# AT32F457xx_v2 register map
Vendor: Keil; Series: AT32F457; File version: 1.0
CPU: CM4 r0p1, little endian, no MPU, FPU, 4 interrupt priority bits
Registers are 32-bit, read-write, reset 0x0 unless marked. A register's access mark holds for its fields unless they carry their own. Offsets are from the block's base; [hi:lo] are bit positions; {n}, {i} and the like mark numbered series; 'fields as' and 'values as' point back to an identical list.

## ERTC — Real-time clock
Base 0x40002800
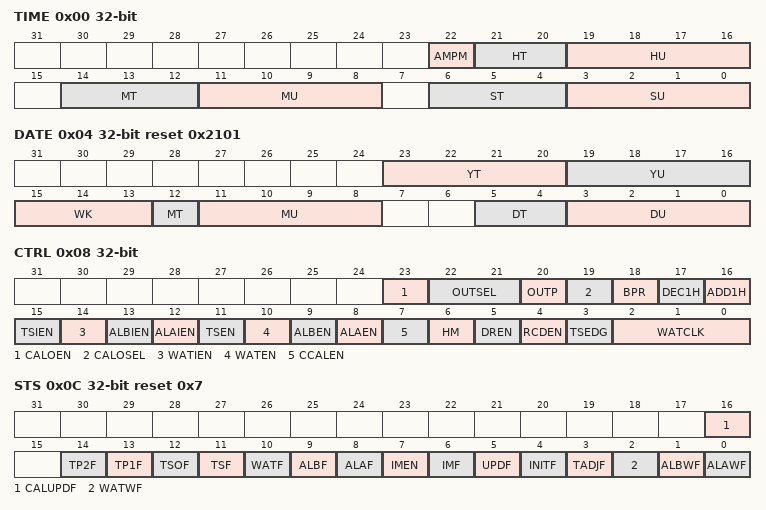
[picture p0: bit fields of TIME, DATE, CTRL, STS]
0x00 TIME
  [22] AMPM — AM/PM notation
  [21:20] HT — Hour tens
  [19:16] HU — Hour units
  [14:12] MT — Minute tens
  [11:8] MU — Minute units
  [6:4] ST — Second tens
  [3:0] SU — Second units
0x04 DATE reset 0x2101
  [23:20] YT — Year tens
  [19:16] YU — Year units
  [15:13] WK — Week
  [12] MT — Month tens
  [11:8] MU — Month units
  [5:4] DT — Date tens
  [3:0] DU — Date units
0x08 CTRL — control register
  [23] CALOEN — Calibration output enable
  [22:21] OUTSEL — Output source selection
  [20] OUTP — Output polarity
  [19] CALOSEL — Calibration output selection
  [18] BPR — Battery power domain data register
  [17] DEC1H — Decrease 1 hour
  [16] ADD1H — Add 1 hour
  [15] TSIEN — Timestamp interrupt enable
  [14] WATIEN — Wakeup timer interrupt enable
  [13] ALBIEN — Alarm B interrupt enable
  [12] ALAIEN — Alarm A interrupt enable
  [11] TSEN — Timestamp enable
  [10] WATEN — Wakeup timer enable
  [9] ALBEN — Alarm B enable
  [8] ALAEN — Alarm A enable
  [7] CCALEN — Coarse calibration enable
  [6] HM — Hour mode
  [5] DREN — Date/time register direct read enable
  [4] RCDEN — Reference clock detection enable
  [3] TSEDG — Timestamp trigger edge
  [2:0] WATCLK — Wakeup timer clock selection
0x0C STS reset 0x7 — initialization and status register
  [16] CALUPDF ro — Calibration value update completed flag
  [14] TP2F — Tamper detection 2 flag
  [13] TP1F — Tamper detection 1 flag
  [12] TSOF — Timestamp overflow flag
  [11] TSF — Timestamp flag
  [10] WATF — Wakeup timer flag
  [9] ALBF — Alarm B flag
  [8] ALAF — Alarm A flag
  [7] IMEN — Initialization mode enable
  [6] IMF ro — Enter initialization mode flag
  [5] UPDF — Calendar update flag
  [4] INITF ro — Calendar initialization flag
  [3] TADJF — Time adjustment flag
  [2] WATWF ro — Wakeup timer register allows write flag
  [1] ALBWF ro — Alarm B register allows write flag
  [0] ALAWF ro — Alarm A register allows write flag
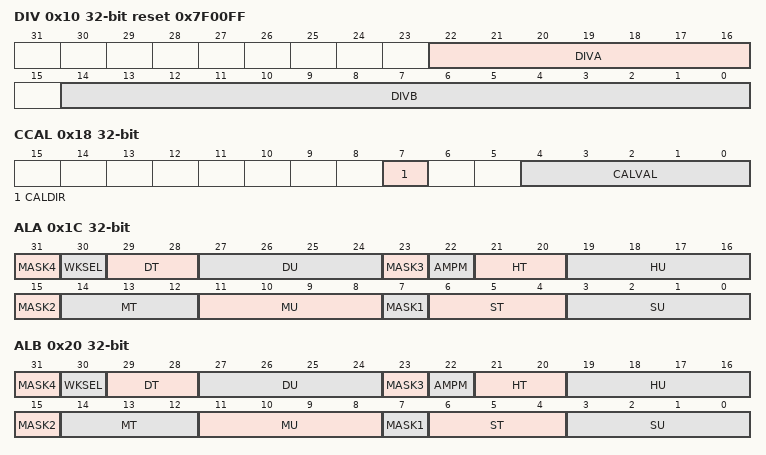
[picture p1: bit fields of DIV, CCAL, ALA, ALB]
0x10 DIV reset 0x7F00FF — Diveder register
  [22:16] DIVA — Diveder A
  [14:0] DIVB — Diveder B
0x14 WAT reset 0xFFFF — Wakeup timer register
  [15:0] VAL — Wakeup timer reload value
0x18 CCAL — Calibration register
  [7] CALDIR — Calibration direction
  [4:0] CALVAL — Calibration value
0x1C ALA — Alarm A register
  [31] MASK4 — Date/week mask
  [30] WKSEL — Date/week mode select
  [29:28] DT — Date tens
  [27:24] DU — Date units
  [23] MASK3 — Hours mask
  [22] AMPM
  [21:20] HT — Hour tens
  [19:16] HU — Hour units
  [15] MASK2 — Minutes mask
  [14:12] MT — Minute tens
  [11:8] MU — Minute units
  [7] MASK1 — Seconds mask
  [6:4] ST — Second tens
  [3:0] SU — Second units
0x20 ALB — Alarm B register
  fields as ALA
0x24 WP wo — write protection register
  [7:0] CMD — Command register
0x28 SBS ro — sub second register
  [15:0] SBS — Sub second value
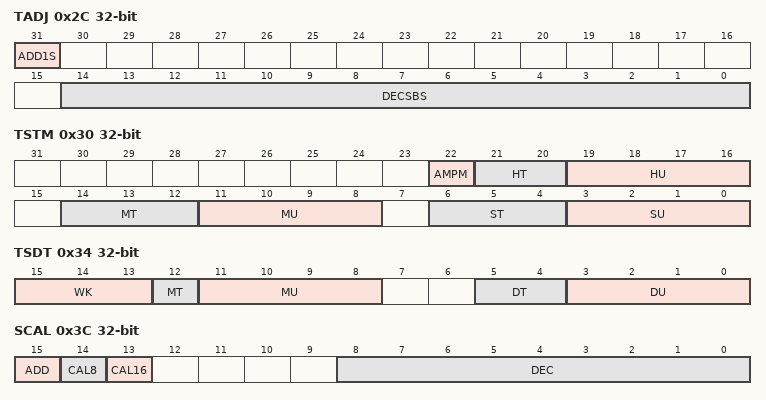
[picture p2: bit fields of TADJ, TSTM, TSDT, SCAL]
0x2C TADJ wo — time adjust register
  [31] ADD1S — Add 1 second
  [14:0] DECSBS — Decrease sub-second value
0x30 TSTM ro — time stamp time register
  [22] AMPM
  [21:20] HT — Hour tens
  [19:16] HU — Hour units
  [14:12] MT — Minute tens
  [11:8] MU — Minute units
  [6:4] ST — Second tens
  [3:0] SU — Second units
0x34 TSDT ro — timestamp date register
  [15:13] WK — Week
  [12] MT — Month tens
  [11:8] MU — Month units
  [5:4] DT — Date tens
  [3:0] DU — Date units
0x38 TSSBS ro — timestamp sub second register
  [15:0] SBS — Sub second value
0x3C SCAL — calibration register
  [15] ADD — Add ERTC clock
  [14] CAL8 — 8-second calibration period
  [13] CAL16 — 16 second calibration period
  [8:0] DEC — Decrease ERTC clock
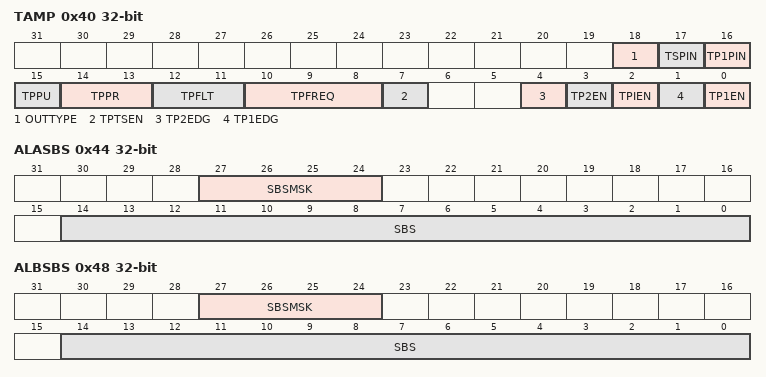
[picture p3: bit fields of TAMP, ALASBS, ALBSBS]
0x40 TAMP — tamper and alternate function configuration register
  [18] OUTTYPE — Output type
  [17] TSPIN — Time stamp detection pin selection
  [16] TP1PIN — Tamper detection pin selection
  [15] TPPU — Tamper detection pull-up
  [14:13] TPPR — Tamper detection pre-charge time
  [12:11] TPFLT — Tamper detection filter time
  [10:8] TPFREQ — Tamper detection frequency
  [7] TPTSEN — Tamper detection timestamp enable
  [4] TP2EDG — Tamper detection 2 valid edge
  [3] TP2EN — Tamper detection 2 enable
  [2] TPIEN — Tamper detection interrupt enable
  [1] TP1EDG — Tamper detection 1 valid edge
  [0] TP1EN — Tamper detection 1 enable
0x44 ALASBS — alarm A sub second register
  [27:24] SBSMSK — Sub-second mask
  [14:0] SBS — Sub-seconds value
0x48 ALBSBS — alarm B sub second register
  [27:24] SBSMSK — Sub-second mask
  [14:0] SBS — Sub-seconds value
{0x4C+4i} BPR{i}DT (i=1..20) — Battery powered domain register
  [31:0] DT — Battery powered domain data

## Notices in the file
Copyright (C) 2012-2014 ARM Limited. All rights reserved.
Purpose: System Viewer Description (SVD) Example (Schema Version 1.1)
This is a description of a none-existent and incomplete device
for demonstration purposes only.
Redistribution and use in source and binary forms, with or without
modification, are permitted provided that the following conditions are met:
- Redistributions of source code must retain the above copyright
notice, this list of conditions and the following disclaimer.
- Redistributions in binary form must reproduce the above copyright
notice, this list of conditions and the following disclaimer in the
documentation and/or other materials provided with the distribution.
- Neither the name of ARM nor the names of its contributors may be used
to endorse or promote products derived from this software without
specific prior written permission.
THIS SOFTWARE IS PROVIDED BY THE COPYRIGHT HOLDERS AND CONTRIBUTORS "AS IS"
AND ANY EXPRESS OR IMPLIED WARRANTIES, INCLUDING, BUT NOT LIMITED TO, THE
IMPLIED WARRANTIES OF MERCHANTABILITY AND FITNESS FOR A PARTICULAR PURPOSE
ARE DISCLAIMED. IN NO EVENT SHALL COPYRIGHT HOLDERS AND CONTRIBUTORS BE
LIABLE FOR ANY DIRECT, INDIRECT, INCIDENTAL, SPECIAL, EXEMPLARY, OR
CONSEQUENTIAL DAMAGES (INCLUDING, BUT NOT LIMITED TO, PROCUREMENT OF
SUBSTITUTE GOODS OR SERVICES; LOSS OF USE, DATA, OR PROFITS; OR BUSINESS
INTERRUPTION) HOWEVER CAUSED AND ON ANY THEORY OF LIABILITY, WHETHER IN
CONTRACT, STRICT LIABILITY, OR TORT (INCLUDING NEGLIGENCE OR OTHERWISE)
ARISING IN ANY WAY OUT OF THE USE OF THIS SOFTWARE, EVEN IF ADVISED OF THE
POSSIBILITY OF SUCH DAMAGE.
